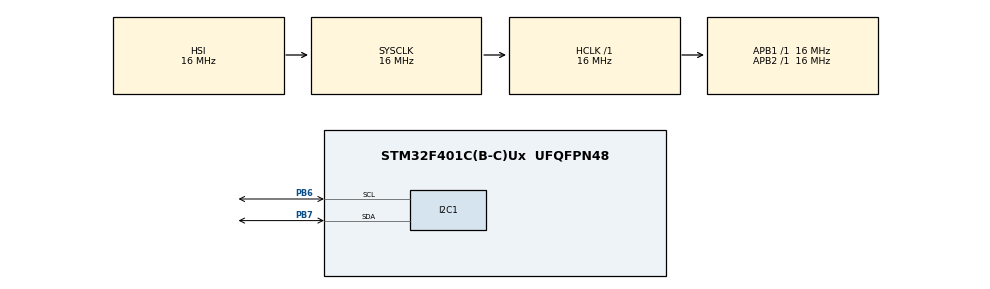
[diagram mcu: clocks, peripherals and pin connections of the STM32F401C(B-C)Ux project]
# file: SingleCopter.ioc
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I2C1.I2C_Mode=I2C_Fast
Mcu.Family=STM32F4
Mcu.Name=STM32F401C(B-C)Ux
Mcu.Package=UFQFPN48
NVIC.PriorityGroup=NVIC_PRIORITYGROUP_4
PA13.Mode=Serial_Wire
PA13.Signal=SYS_JTMS-SWDIO
PA14.Mode=Serial_Wire
PA14.Signal=SYS_JTCK-SWCLK
PB6.Mode=I2C
PB6.Signal=I2C1_SCL
PB7.Mode=I2C
PB7.Signal=I2C1_SDA
ProjectManager.HeapSize=0x200
ProjectManager.StackSize=0x400
ProjectManager.TargetToolchain=STM32CubeIDE
RCC.AHBFreq_Value=16000000
RCC.APB1Freq_Value=16000000
RCC.APB2Freq_Value=16000000
RCC.CortexFreq_Value=16000000
RCC.HSE_VALUE=25000000
RCC.HSI_VALUE=16000000
RCC.LSE_VALUE=32768
RCC.SYSCLKFreq_VALUE=16000000
RCC.VCOOutputFreq_Value=192000000
board=custom

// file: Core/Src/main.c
/* USER CODE BEGIN Header */
/**
  ******************************************************************************
  * @file           : main.c
  * @brief          : Main program body
  ******************************************************************************
  * @attention
  *
  * Copyright (c) 2024 STMicroelectronics.
  * All rights reserved.
  *
  * This software is licensed under terms that can be found in the LICENSE file
  * in the root directory of this software component.
  * If no LICENSE file comes with this software, it is provided AS-IS.
  *
  ******************************************************************************
  */
/* USER CODE END Header */
#include "main.h"

/* USER CODE BEGIN PD */
#define LSB_Sensitivity 16.4

/* Controller parameters */
#define PID_KP  100.0f
#define PID_KI  0.0f
#define PID_KD  10.0f

#define PID_TAU 0.02f

#define PID_LIM_MIN 1000.0f
#define PID_LIM_MAX 2000.0f

#define PID_LIM_MIN_INT -400.0f
#define PID_LIM_MAX_INT  400.0f

#define SAMPLE_TIME_S 0.005f

/* USER CODE END PD */

I2C_HandleTypeDef hi2c1;

/* USER CODE BEGIN PV */
extern float q0, q1, q2, q3;
extern float pitch, roll, yaw;
extern short gyro[3];
float gx, gy, gz;
float gx_angle, gy_angle, gz_angle;
uint32_t loop_timer;
/* Initialize PID controller */
PIDController pid_roll = {1.0, PID_KI, PID_KD,
						  PID_TAU,
						  -100, 100,
						  -10, 10,
						  SAMPLE_TIME_S};

PIDController pid_roll_rate = {PID_KP, PID_KI, PID_KD,
                               PID_TAU,
                               PID_LIM_MIN, PID_LIM_MAX,
						       PID_LIM_MIN_INT, PID_LIM_MAX_INT,
                               SAMPLE_TIME_S};
/* USER CODE END PV */

void SystemClock_Config(void);
static void MX_GPIO_Init(void);
static void MX_I2C1_Init(void);
extern void DMP_Init();
extern void Read_DMP();

int main(void)
{

  /* MCU Configuration--------------------------------------------------------*/

  /* Reset of all peripherals, Initializes the Flash interface and the Systick. */
  HAL_Init();

  /* Configure the system clock */
  SystemClock_Config();

  /* Initialize all configured peripherals */
  MX_GPIO_Init();
  MX_I2C1_Init();
  /* USER CODE BEGIN 2 */
  DMP_Init();

  PIDController_Init(&pid_roll);

  float avg_gyro_x, avg_gyro_y, avg_gyro_z;
  do
  {
	  avg_gyro_x=avg_gyro_y=avg_gyro_z=0;
	  for (uint32_t i =0; i<100 ;i++)
	  {
		  Read_DMP();
		  avg_gyro_x += abs((float)gyro[0]);
		  avg_gyro_y += abs((float)gyro[1]);
		  avg_gyro_z += abs((float)gyro[2]);
	  }
	  avg_gyro_x/=100;
	  avg_gyro_y/=100;
	  avg_gyro_z/=100;
  }
  while(avg_gyro_x>5 || avg_gyro_y>5 || avg_gyro_z>5);

  float offset_gx=0;
  float offset_gy=0;
  float offset_gz=0;

  for(uint32_t i=0 ; i<100; i++)
  {
	  Read_DMP();
	  offset_gx+=(float)gyro[0];
	  offset_gy+=(float)gyro[1];
	  offset_gz+=(float)gyro[2];
  }

  offset_gx/=100;
  offset_gy/=100;
  offset_gz/=100;
  /* USER CODE END 2 */

  /* Infinite loop */
  /* USER CODE BEGIN WHILE */
  gx_angle=gy_angle=gz_angle=0;
  gx=gy=gz=0;
  float setpoint_roll=.00f;
  while (1)
  {

	setpoint_roll=0.0f;
    /* USER CODE END WHILE */
    /* USER CODE BEGIN 3 */
	loop_timer = HAL_GetTick();
	Read_DMP();

	gx = (((float)gyro[0]) - offset_gx) / LSB_Sensitivity;
	gy = (((float)gyro[1]) - offset_gy) / LSB_Sensitivity;
	gz = (((float)gyro[2]) - offset_gz) / LSB_Sensitivity;

	gx_angle += gx*SAMPLE_TIME_S;
	gy_angle += gy*SAMPLE_TIME_S;
	gz_angle += gz*SAMPLE_TIME_S;

	PIDController_Update(&pid_roll, setpoint_roll, roll);
	PIDController_Update(&pid_roll_rate, pid_roll.out, gx);
	//integrate the pitch, roll, yaw angle every 5 milliseconds.
	while (HAL_GetTick() - loop_timer < 5 );
  }
  /* USER CODE END 3 */
}

void SystemClock_Config(void)
{
  RCC_OscInitTypeDef RCC_OscInitStruct = {0};
  RCC_ClkInitTypeDef RCC_ClkInitStruct = {0};

  /** Configure the main internal regulator output voltage
  */
  __HAL_RCC_PWR_CLK_ENABLE();
  __HAL_PWR_VOLTAGESCALING_CONFIG(PWR_REGULATOR_VOLTAGE_SCALE2);

  /** Initializes the RCC Oscillators according to the specified parameters
  * in the RCC_OscInitTypeDef structure.
  */
  RCC_OscInitStruct.OscillatorType = RCC_OSCILLATORTYPE_HSI;
  RCC_OscInitStruct.HSIState = RCC_HSI_ON;
  RCC_OscInitStruct.HSICalibrationValue = RCC_HSICALIBRATION_DEFAULT;
  RCC_OscInitStruct.PLL.PLLState = RCC_PLL_NONE;
  if (HAL_RCC_OscConfig(&RCC_OscInitStruct) != HAL_OK)
  {
    Error_Handler();
  }

  /** Initializes the CPU, AHB and APB buses clocks
  */
  RCC_ClkInitStruct.ClockType = RCC_CLOCKTYPE_HCLK|RCC_CLOCKTYPE_SYSCLK
                              |RCC_CLOCKTYPE_PCLK1|RCC_CLOCKTYPE_PCLK2;
  RCC_ClkInitStruct.SYSCLKSource = RCC_SYSCLKSOURCE_HSI;
  RCC_ClkInitStruct.AHBCLKDivider = RCC_SYSCLK_DIV1;
  RCC_ClkInitStruct.APB1CLKDivider = RCC_HCLK_DIV1;
  RCC_ClkInitStruct.APB2CLKDivider = RCC_HCLK_DIV1;

  if (HAL_RCC_ClockConfig(&RCC_ClkInitStruct, FLASH_LATENCY_0) != HAL_OK)
  {
    Error_Handler();
  }
}

static void MX_I2C1_Init(void)
{

  hi2c1.Instance = I2C1;
  hi2c1.Init.ClockSpeed = 400000;
  hi2c1.Init.DutyCycle = I2C_DUTYCYCLE_2;
  hi2c1.Init.OwnAddress1 = 0;
  hi2c1.Init.AddressingMode = I2C_ADDRESSINGMODE_7BIT;
  hi2c1.Init.DualAddressMode = I2C_DUALADDRESS_DISABLE;
  hi2c1.Init.OwnAddress2 = 0;
  hi2c1.Init.GeneralCallMode = I2C_GENERALCALL_DISABLE;
  hi2c1.Init.NoStretchMode = I2C_NOSTRETCH_DISABLE;
  if (HAL_I2C_Init(&hi2c1) != HAL_OK)
  {
    Error_Handler();
  }

}

static void MX_GPIO_Init(void)
{

  /* GPIO Ports Clock Enable */
  __HAL_RCC_GPIOA_CLK_ENABLE();
  __HAL_RCC_GPIOB_CLK_ENABLE();

}

void Error_Handler(void)
{
  __disable_irq();
  while (1)
  {
  }
}
